VERSION ""

NS_ :

BS_:

BU_:

BO_ 3221225472 VECTOR__INDEPENDENT_SIG_MSG: 0 Vector__XXX
 SG_ V4 : 0|16@1+ (1,0) [0|0] "" Vector__XXX
 SG_ V3 : 0|16@1+ (1,0) [0|0] "" Vector__XXX
 SG_ V2 : 0|16@1+ (1,0) [0|0] "" Vector__XXX
 SG_ V1 : 0|16@1+ (1,0) [0|0] "" Vector__XXX
 SG_ V4 : 0|16@1+ (1,0) [0|0] "" Vector__XXX
 SG_ V3 : 0|16@1+ (1,0) [0|0] "" Vector__XXX
 SG_ V2 : 0|16@1+ (1,0) [0|0] "" Vector__XXX
 SG_ V1 : 0|16@1+ (1,0) [0|0] "" Vector__XXX

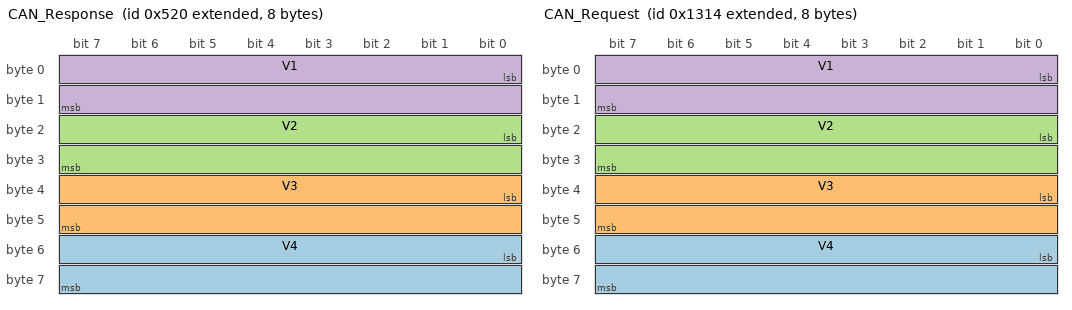
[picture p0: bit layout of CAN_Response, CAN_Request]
BO_ 2147484960 CAN_Response: 8 Vector__XXX
 SG_ V4 : 48|16@1+ (1,0) [0|0] "" Vector__XXX
 SG_ V3 : 32|16@1+ (1,0) [0|0] "" Vector__XXX
 SG_ V2 : 16|16@1+ (1,0) [0|0] "" Vector__XXX
 SG_ V1 : 0|16@1+ (1,0) [0|0] "" Vector__XXX

BO_ 2147488532 CAN_Request: 8 Vector__XXX
 SG_ V4 : 48|16@1+ (1,0) [0|0] "" Vector__XXX
 SG_ V3 : 32|16@1+ (1,0) [0|0] "" Vector__XXX
 SG_ V2 : 16|16@1+ (1,0) [0|0] "" Vector__XXX
 SG_ V1 : 0|16@1+ (1,0) [0|0] "" Vector__XXX

CM_ BO_ 3221225472 "This is a message for not used signals, created by Vector CANdb++ DBC OLE DB Provider.";
BA_DEF_  "BusType" STRING ;
BA_DEF_DEF_  "BusType" "CAN";
